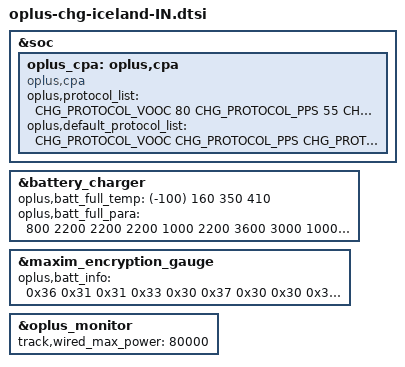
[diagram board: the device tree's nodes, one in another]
/* IN QBG */
#include "oplus-chg-iceland-common.dtsi"
#include "oplus-chg-iceland-qbg.dtsi"
#include "oplus-chg-iceland-80w.dtsi"

&soc {
	oplus_cpa: oplus,cpa {
		compatible = "oplus,cpa";
		/* format: <protocol_type power_w> */
		oplus,protocol_list = <	CHG_PROTOCOL_VOOC 80
					CHG_PROTOCOL_PPS  55
					CHG_PROTOCOL_PD   13
					CHG_PROTOCOL_QC   13>;
		oplus,default_protocol_list = <	CHG_PROTOCOL_VOOC
						CHG_PROTOCOL_PPS
						CHG_PROTOCOL_PD>;
	};
};

&battery_charger {
	oplus,batt_full_temp = <(-100) 160 350 410>;
	oplus,batt_full_para = <800 2200 2200 2200    /* normal pd qc */
				1000 2200 3600 3000      /* svooc */
				1000 2200 3600 3000      /* oplus ufcs */
				1000 2200 3600 3000      /* oplus pps */
				1000 2200 3600 3000      /* third ufcs */
				1000 2200 3600 3000      /* third pps */
				1500 1500 1300 1300>;    /* ffc */
};

&maxim_encryption_gauge {
	/* CN:611307000110
	   IN:611307000112
	*/
	oplus,batt_info = /bits/ 8 <0x36 0x31 0x31 0x33 0x30 0x37 0x30 0x30 0x30 0x31 0x31 0x30
				    0x36 0x31 0x31 0x33 0x30 0x37 0x30 0x30 0x30 0x31 0x31 0x32>;
};

&oplus_monitor {
	track,wired_max_power = <80000>;
};
